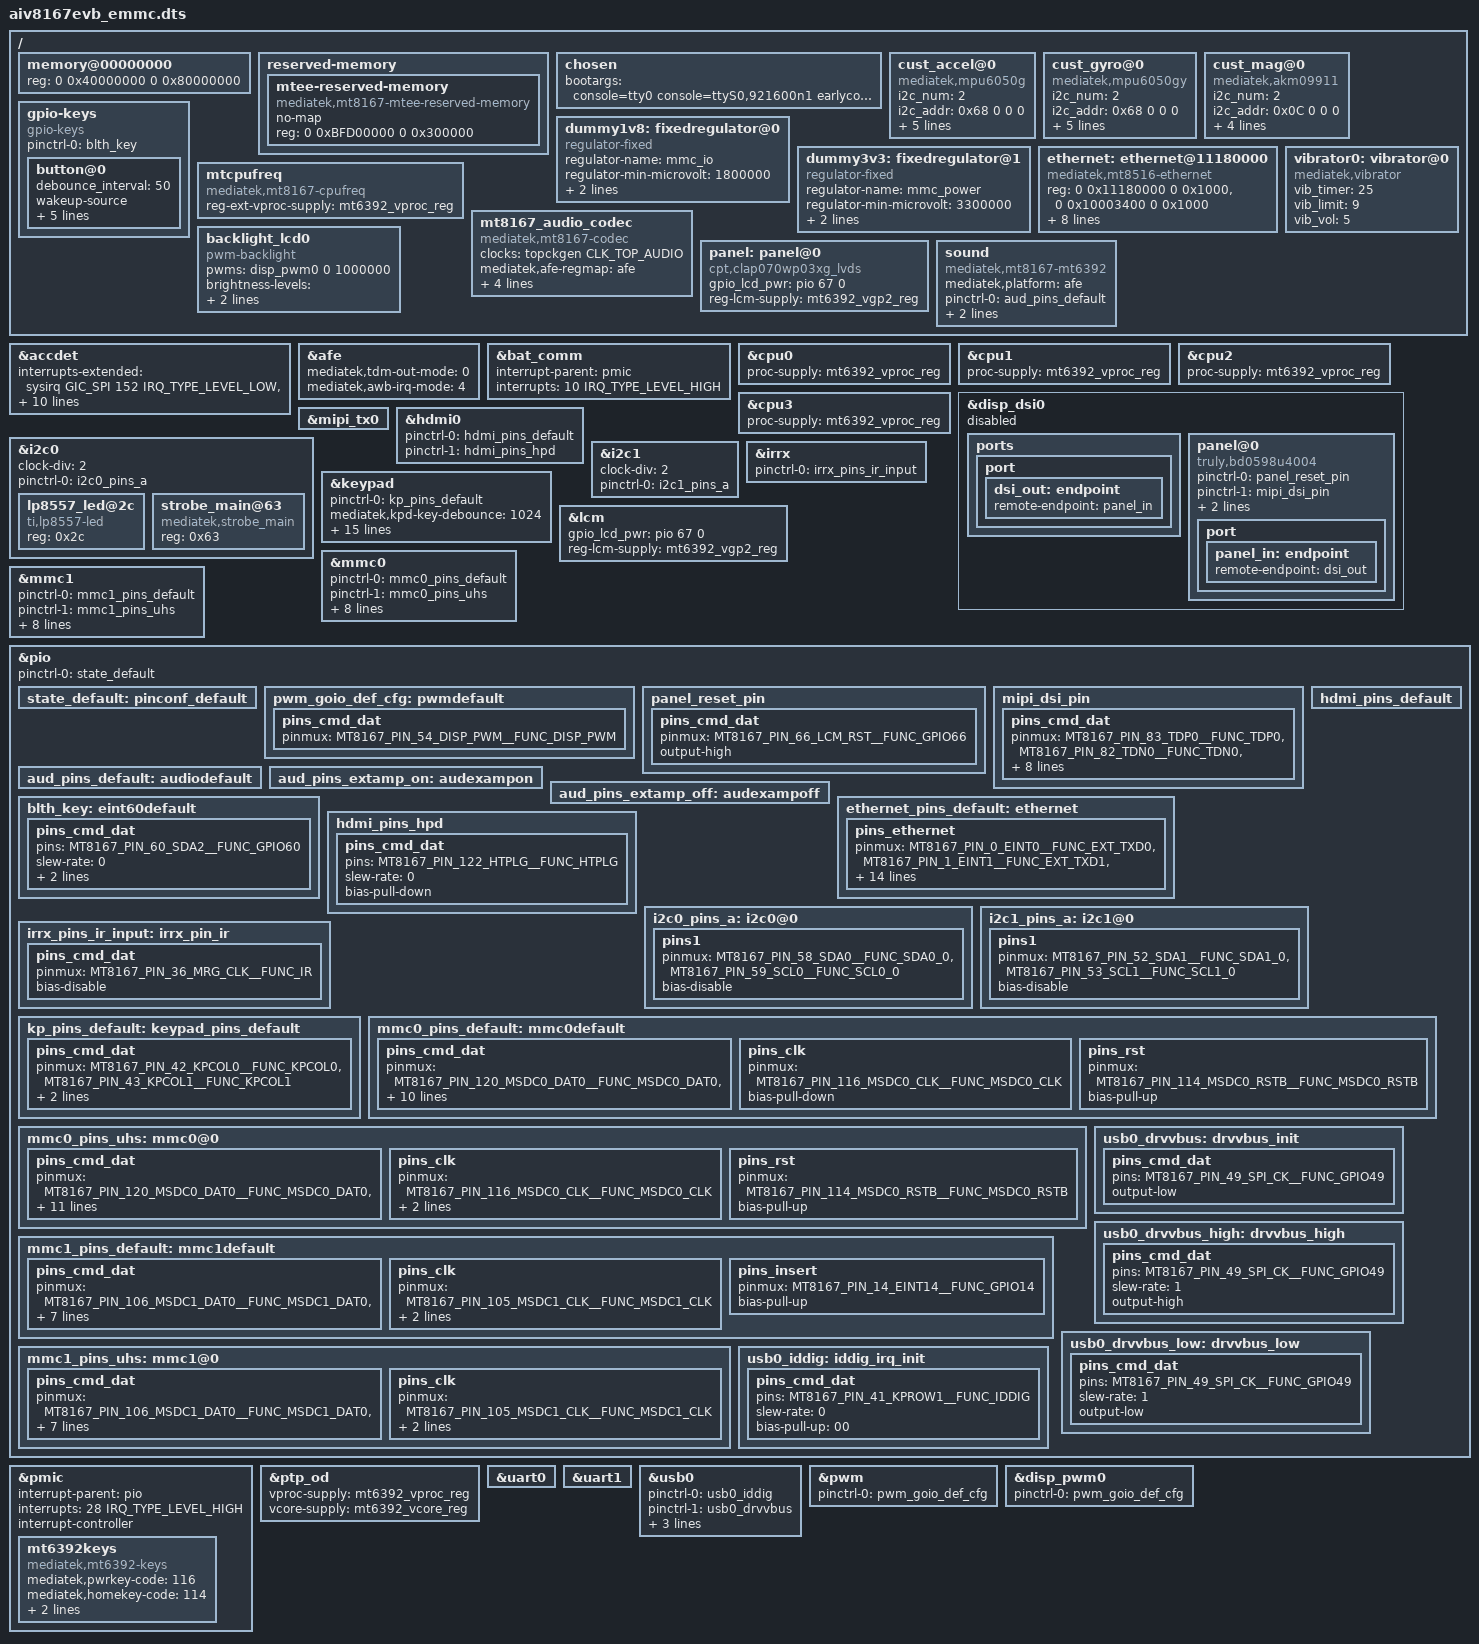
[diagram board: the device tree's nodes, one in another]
/*
 * Copyright (c) 2014-2015 MediaTek Inc.
 *
 * This program is free software; you can redistribute it and/or modify
 * it under the terms of the GNU General Public License version 2 as
 * published by the Free Software Foundation.
 *
 * This program is distributed in the hope that it will be useful,
 * MERCHANTABILITY or FITNESS FOR A PARTICULAR PURPOSE.  See the
 * GNU General Public License for more details.
 */

/dts-v1/;

#include "mt8167.dtsi"
#include "mt6392.dtsi"
#include <dt-bindings/gpio/gpio.h>

/ {
	/*
	IMPORTANT: 	If you modify the memory size,please modify mtee-reserved-memory size together.
					mtee must be located begin with the last 3MB of dram
	*/

	memory@00000000 {
		device_type = "memory";
		reg = <0 0x40000000 0 0x80000000>;
	};

	reserved-memory {
		mtee-reserved-memory {
			compatible = "mediatek,mt8167-mtee-reserved-memory";
			no-map;
			reg = <0 0xBFD00000 0 0x300000>;
		};
	};

	/* chosen */
	chosen {
		bootargs = "console=tty0 console=ttyS0,921600n1 earlycon=uart8250,mmio32,0x11005000 root=/dev/mmcblk0p7 vmalloc=496M androidboot.hardware=aud8516p1_linux";
	};

/* sensor standardization */
	cust_accel@0 {
		compatible = "mediatek,mpu6050g";
		i2c_num	= <2>;
		i2c_addr = <0x68 0 0 0>;
		direction = <7>;
		power_id = <0xffff>;
		power_vol = <0>;
		firlen = <0>;
		is_batch_supported = <0>;
	};

	cust_gyro@0 {
		compatible = "mediatek,mpu6050gy";
		i2c_num = <2>;
		i2c_addr = <0x68 0 0 0>;
		direction = <7>;
		power_id = <0xffff>;
		power_vol = <0>;
		firlen = <0>;
		is_batch_supported = <0>;
	};

	cust_mag@0 {
		compatible = "mediatek,akm09911";
		i2c_num = <2>;
		i2c_addr = <0x0C 0 0 0>;
		direction = <6>;
		power_id = <0xffff>;
		power_vol = <0>;
		is_batch_supported			= <0>;
	};
/* sensor gpio standization */

	dummy1v8: fixedregulator@0 {
		compatible = "regulator-fixed";
		regulator-name = "mmc_io";
		regulator-min-microvolt = <1800000>;
		regulator-max-microvolt = <1800000>;
		regulator-always-on;
	};

	dummy3v3: fixedregulator@1 {
		compatible = "regulator-fixed";
		regulator-name = "mmc_power";
		regulator-min-microvolt = <3300000>;
		regulator-max-microvolt = <3300000>;
		regulator-always-on;
	};

	ethernet: ethernet@11180000 {
		compatible = "mediatek,mt8516-ethernet";
		reg = <0 0x11180000 0 0x1000>,
		      <0 0x10003400 0 0x1000>;
		interrupts = <GIC_SPI 111 IRQ_TYPE_LEVEL_LOW>;
		eth-gpios = <&pio 34 0>;
		clocks = <&topckgen CLK_TOP_RG_ETH>,
			 <&topckgen CLK_TOP_66M_ETH>,
			 <&topckgen CLK_TOP_133M_ETH>;
		clock-names = "core", "reg", "trans";
		eth-regulator-supply = <&mt6392_vmch_reg>;
		pinctrl-names = "default";
		pinctrl-0 = <&ethernet_pins_default>;
		mac-address = [00 00 00 00 00 00];
		/*local-mac-address = [00 0C E7 06 00 00];*/
		status = "okay";
	};

	gpio-keys {
		compatible = "gpio-keys";
		pinctrl-names = "default";
		pinctrl-0 = <&blth_key>;

		button@0 {
			debounce_interval = <50>;
			wakeup-source;
			gpio-key,wakeup = <1>;
			gpios = <&pio 60 1>;
			label = "Bluetooth";
			linux,input-type = <0x1>;
			linux,code = <237>;
		};
	};

	mtcpufreq {
		compatible = "mediatek,mt8167-cpufreq";
		reg-ext-vproc-supply = <&mt6392_vproc_reg>;
	};

	mt8167_audio_codec: mt8167_audio_codec {
		compatible = "mediatek,mt8167-codec";
		clocks = <&topckgen CLK_TOP_AUDIO>;
		clock-names = "bus";
		mediatek,afe-regmap = <&afe>;
		mediatek,apmixedsys-regmap = <&apmixedsys>;
		mediatek,pwrap-regmap = <&pwrap>;
		mediatek,speaker-mode = <0>; /* 0(CLASSD) 1(CLASSAB) */
		mediatek,dmic-wire-mode = <1>; /* 0(ONE_WIRE) 1(TWO_WIRE) */
	};

	backlight_lcd0: backlight_lcd0 {
       compatible = "pwm-backlight";
       pwms = <&disp_pwm0 0 1000000>;
       brightness-levels = <
           0  16  32  48  64  80  96 112
           128 144 160 176 192 208 224 240
           255
       >;
       default-brightness-level = <5>;
	};

	panel: panel@0 {
		compatible = "cpt,clap070wp03xg_lvds";
		gpio_lcd_pwr = <&pio 67 0>;
		reg-lcm-supply = <&mt6392_vgp2_reg>;
	};



	sound: sound {
		compatible = "mediatek,mt8167-mt6392";
		mediatek,platform = <&afe>;
		pinctrl-names = "default", "extamp_on", "extamp_off";
		pinctrl-0 = <&aud_pins_default>;
		pinctrl-1 = <&aud_pins_extamp_on>;
		pinctrl-2 = <&aud_pins_extamp_off>;
		status = "okay";
	};

	vibrator0:vibrator@0 {
		compatible = "mediatek,vibrator";
		vib_timer = <25>;
		vib_limit = <9>;
		vib_vol= <5>;
	};
};

&accdet {
	interrupts-extended = <&sysirq GIC_SPI 152 IRQ_TYPE_LEVEL_LOW>,
			<&pio 16 IRQ_TYPE_LEVEL_HIGH>;
	eint-debounce = <256000>;
	accdet-gpio = <&pio 16 0>;
	accdet-mic-vol = <7>;
	headset-mode-setting = <0x500 0x500 1 0x1f0 0x800 0x800 0x20>;
	accdet-plugout-debounce = <20>;
	/*1:ACC mode, 2:low cost without in bias, 6:low cost with in bias*/
	accdet-mic-mode = <1>;
	/*0--MD_MAX--UP_MAX--DW_MAX*/
	headset-three-key-threshold = <0 80 220 500>;
	/*0--MD_MAX--VOICE_MAX--UP_MAX--DW_MAX*/
	headset-four-key-threshold = <0 58 121 192 450>;
	status = "okay";
};

&afe {
	/* 0(HDMI) 1(I2S) 2(TDM) */
	mediatek,tdm-out-mode = <0>;
	/* 0(IR1) 1(IRQ2) 4(IRQ7)*/
	mediatek,awb-irq-mode = <4>;
};

&bat_comm {
	interrupt-parent = <&pmic>;
	interrupts = <10 IRQ_TYPE_LEVEL_HIGH>;
};

&cpu0 {
	proc-supply = <&mt6392_vproc_reg>;
};

&cpu1 {
	proc-supply = <&mt6392_vproc_reg>;
};

&cpu2 {
	proc-supply = <&mt6392_vproc_reg>;
};

&cpu3 {
	proc-supply = <&mt6392_vproc_reg>;
};

&disp_dsi0 {
	status = "disabled";
	#address-cells = <1>;
	#size-cells = <0>;
	ports {
		port {
			dsi_out: endpoint {
				remote-endpoint = <&panel_in>;
			};
		};
	};

	panel@0 {
		compatible = "truly,bd0598u4004";
		pinctrl-names = "default", "mipi_dsi_pin";
		pinctrl-0 = <&panel_reset_pin>;
		pinctrl-1 = <&mipi_dsi_pin>;
		reset-gpios = <&pio 66 0>;
		reg = <0>;

		port {
			panel_in: endpoint {
				remote-endpoint = <&dsi_out>;
			};
		};
	};
};

&mipi_tx0 {
	status = "okay";
};

&hdmi0 {
	pinctrl-names = "default", "hdmi_hpd";
	pinctrl-0 = <&hdmi_pins_default>;
	pinctrl-1 = <&hdmi_pins_hpd>;
	status = "okay";
};

&i2c0 {
	clock-div = <2>;
	pinctrl-names = "default";
	pinctrl-0 = <&i2c0_pins_a>;
	status = "okay";

	lp8557_led@2c {
		compatible = "ti,lp8557-led";
		reg = <0x2c>;
	};

	strobe_main@63 {
		compatible = "mediatek,strobe_main";
		reg = <0x63>;
	};
};

&i2c1 {
	clock-div = <2>;
	pinctrl-names = "default";
	pinctrl-0 = <&i2c1_pins_a>;
	status = "okay";
};

&irrx {
	pinctrl-names = "default";
	pinctrl-0 = <&irrx_pins_ir_input>;
	status = "okay";
};

&keypad {
	pinctrl-names = "default";
	pinctrl-0 = <&kp_pins_default>;

	mediatek,kpd-key-debounce = <1024>;
	mediatek,kpd-sw-pwrkey = <116>;
	mediatek,kpd-hw-pwrkey = <8>;
	mediatek,kpd-sw-rstkey  = <114>;
	mediatek,kpd-hw-rstkey = <17>;
	mediatek,kpd-use-extend-type = <0>;
	/*HW Keycode [0~71] -> Linux Keycode*/
	mediatek,kpd-hw-map-num = <72>;
	mediatek,kpd-hw-init-map = <115 113 0 0 0 0 0 0 0 0 0 0 0 0 0 0 0 0 0 0 0 0 0 0
			0 0 0 0 0 0 0 0 0 0 0 0 0 0 0 0 0 0 0 0 0 0 0 0
			0 0 0 0 0 0 0 0 0 0 0 0 0 0 0 0 0 0 0 0 0 0 0 0 >;
	mediatek,kpd-pwrkey-eint-gpio = <0>;
	mediatek,kpd-pwkey-gpio-din  = <0>;
	mediatek,kpd-hw-dl-key0 = <0>;
	mediatek,kpd-hw-dl-key1 = <17>;
	mediatek,kpd-hw-dl-key2 = <8>;
	mediatek,kpd-hw-recovery-key = <17>;
	mediatek,kpd-hw-factory-key  = <0>;
};

&lcm {
	gpio_lcd_pwr = <&pio 67 0>;
	reg-lcm-supply = <&mt6392_vgp2_reg>;
};

&mmc0 {
	pinctrl-names = "default", "state_uhs";
	pinctrl-0 = <&mmc0_pins_default>;
	pinctrl-1 = <&mmc0_pins_uhs>;
	status = "okay";
	bus-width = <8>;
	max-frequency = <200000000>;
	cap-mmc-highspeed;
	mmc-hs200-1_8v;
	cap-mmc-hw-reset;
	vmmc-supply = <&mt6392_vemc3v3_reg>;
	vqmmc-supply = <&mt6392_vio18_reg>;
	non-removable;
};

&mmc1 {
	pinctrl-names = "default", "state_uhs";
	pinctrl-0 = <&mmc1_pins_default>;
	pinctrl-1 = <&mmc1_pins_uhs>;
	status = "okay";
	bus-width = <4>;
	max-frequency = <200000000>;
	cap-sd-highspeed;
	sd-uhs-sdr50;
	sd-uhs-sdr104;
	cd-gpios = <&pio 14 GPIO_ACTIVE_LOW>;
	vmmc-supply = <&mt6392_vmch_reg>;
	vqmmc-supply = <&mt6392_vmc_reg>;
};

&pio {
	pinctrl-names = "default";
	pinctrl-0 = <&state_default>;

	state_default:pinconf_default {
	};


pwm_goio_def_cfg: pwmdefault {
		pins_cmd_dat {
			pinmux = <MT8167_PIN_54_DISP_PWM__FUNC_DISP_PWM>;
			};
};
	panel_reset_pin: panel_reset_pin {
		pins_cmd_dat {
			pinmux = <MT8167_PIN_66_LCM_RST__FUNC_GPIO66>;
			output-high;
		};
	};

	mipi_dsi_pin: mipi_dsi_pin {
		pins_cmd_dat {
			pinmux = <MT8167_PIN_83_TDP0__FUNC_TDP0>,
				<MT8167_PIN_82_TDN0__FUNC_TDN0>,
				<MT8167_PIN_81_TDP1__FUNC_TDP1>,
				<MT8167_PIN_80_TDN1__FUNC_TDN1>,
				<MT8167_PIN_79_TCP__FUNC_TCP>,
				<MT8167_PIN_78_TCN__FUNC_TCN>,
				<MT8167_PIN_77_TDP2__FUNC_TDP2>,
				<MT8167_PIN_76_TDN2__FUNC_TDN2>,
				<MT8167_PIN_75_TDP3__FUNC_TDP3>,
				<MT8167_PIN_74_TDN3__FUNC_TDN3>;
		};
	};

	aud_pins_default: audiodefault {
	};
	aud_pins_extamp_on: audexampon {
	};

	aud_pins_extamp_off: audexampoff {
	};
	
	blth_key: eint60default {
		pins_cmd_dat {
			pins = <MT8167_PIN_60_SDA2__FUNC_GPIO60>;
			slew-rate = <0>;
			bias-pull-up = <MTK_PUPD_SET_R1R0_01>;
			input-enable;
		};
	};

	ethernet_pins_default: ethernet {
		pins_ethernet {
			pinmux = <MT8167_PIN_0_EINT0__FUNC_EXT_TXD0>,
				 <MT8167_PIN_1_EINT1__FUNC_EXT_TXD1>,
				 <MT8167_PIN_2_EINT2__FUNC_EXT_TXD2>,
				 <MT8167_PIN_3_EINT3__FUNC_EXT_TXD3>,
				 <MT8167_PIN_4_EINT4__FUNC_EXT_TXC>,
				 <MT8167_PIN_5_EINT5__FUNC_EXT_RXER>,
				 <MT8167_PIN_6_EINT6__FUNC_EXT_RXC>,
				 <MT8167_PIN_7_EINT7__FUNC_EXT_RXDV>,
				 <MT8167_PIN_8_EINT8__FUNC_EXT_RXD0>,
				 <MT8167_PIN_9_EINT9__FUNC_EXT_RXD1>,
				 <MT8167_PIN_10_EINT10__FUNC_EXT_RXD2>,
				 <MT8167_PIN_11_EINT11__FUNC_EXT_RXD3>,
				 <MT8167_PIN_12_EINT12__FUNC_EXT_TXEN>,
				 <MT8167_PIN_37_MRG_SYNC__FUNC_EXT_COL>,
				 <MT8167_PIN_38_MRG_DI__FUNC_EXT_MDIO>,
				 <MT8167_PIN_39_MRG_DO__FUNC_EXT_MDC>;
		};
	};

	hdmi_pins_default: hdmi_pins_default {
	};

	hdmi_pins_hpd: hdmi_pins_hpd {
		pins_cmd_dat {
			pins = <MT8167_PIN_122_HTPLG__FUNC_HTPLG>;
			slew-rate = <0>;
			bias-pull-down;
		};
	};

	i2c0_pins_a: i2c0@0 {
		pins1 {
			pinmux = <MT8167_PIN_58_SDA0__FUNC_SDA0_0>,
				 <MT8167_PIN_59_SCL0__FUNC_SCL0_0>;
			bias-disable;
		};
	};

	i2c1_pins_a: i2c1@0 {
		pins1 {
			pinmux = <MT8167_PIN_52_SDA1__FUNC_SDA1_0>,
				 <MT8167_PIN_53_SCL1__FUNC_SCL1_0>;
			bias-disable;
		};
	};

	irrx_pins_ir_input: irrx_pin_ir {
		pins_cmd_dat {
		pinmux = <MT8167_PIN_36_MRG_CLK__FUNC_IR>;
		bias-disable;
		};
	};

	kp_pins_default: keypad_pins_default {
		pins_cmd_dat {
			pinmux = <MT8167_PIN_42_KPCOL0__FUNC_KPCOL0>,
			     <MT8167_PIN_43_KPCOL1__FUNC_KPCOL1>;
			input-enable;
			bias-pull-up;
		};
	};

	mmc0_pins_default: mmc0default {
		pins_cmd_dat {
			pinmux = <MT8167_PIN_120_MSDC0_DAT0__FUNC_MSDC0_DAT0>,
				<MT8167_PIN_119_MSDC0_DAT1__FUNC_MSDC0_DAT1>,
				<MT8167_PIN_118_MSDC0_DAT2__FUNC_MSDC0_DAT2>,
				<MT8167_PIN_117_MSDC0_DAT3__FUNC_MSDC0_DAT3>,
				<MT8167_PIN_113_MSDC0_DAT4__FUNC_MSDC0_DAT4>,
				<MT8167_PIN_112_MSDC0_DAT5__FUNC_MSDC0_DAT5>,
				<MT8167_PIN_111_MSDC0_DAT6__FUNC_MSDC0_DAT6>,
				<MT8167_PIN_110_MSDC0_DAT7__FUNC_MSDC0_DAT7>,
				<MT8167_PIN_115_MSDC0_CMD__FUNC_MSDC0_CMD>;
			input-enable;
			bias-pull-up;
		};

		pins_clk {
			pinmux = <MT8167_PIN_116_MSDC0_CLK__FUNC_MSDC0_CLK>;
			bias-pull-down;
		};

		pins_rst {
			pinmux = <MT8167_PIN_114_MSDC0_RSTB__FUNC_MSDC0_RSTB>;
			bias-pull-up;
		};
	};

	mmc0_pins_uhs: mmc0@0{
		pins_cmd_dat {
			pinmux = <MT8167_PIN_120_MSDC0_DAT0__FUNC_MSDC0_DAT0>,
				<MT8167_PIN_119_MSDC0_DAT1__FUNC_MSDC0_DAT1>,
				<MT8167_PIN_118_MSDC0_DAT2__FUNC_MSDC0_DAT2>,
				<MT8167_PIN_117_MSDC0_DAT3__FUNC_MSDC0_DAT3>,
				<MT8167_PIN_113_MSDC0_DAT4__FUNC_MSDC0_DAT4>,
				<MT8167_PIN_112_MSDC0_DAT5__FUNC_MSDC0_DAT5>,
				<MT8167_PIN_111_MSDC0_DAT6__FUNC_MSDC0_DAT6>,
				<MT8167_PIN_110_MSDC0_DAT7__FUNC_MSDC0_DAT7>,
				<MT8167_PIN_115_MSDC0_CMD__FUNC_MSDC0_CMD>;
			input-enable;
			drive-strength = <MTK_DRIVE_6mA>;
			bias-pull-up = <MTK_PUPD_SET_R1R0_01>;
		};

		pins_clk {
			pinmux = <MT8167_PIN_116_MSDC0_CLK__FUNC_MSDC0_CLK>;
			drive-strength = <MTK_DRIVE_8mA>;
			bias-pull-down = <MTK_PUPD_SET_R1R0_10>;
		};

		pins_rst {
			pinmux = <MT8167_PIN_114_MSDC0_RSTB__FUNC_MSDC0_RSTB>;
			bias-pull-up;
		};
	};

	mmc1_pins_default: mmc1default {
		pins_cmd_dat {
			pinmux = <MT8167_PIN_106_MSDC1_DAT0__FUNC_MSDC1_DAT0>,
				<MT8167_PIN_107_MSDC1_DAT1__FUNC_MSDC1_DAT1>,
				<MT8167_PIN_108_MSDC1_DAT2__FUNC_MSDC1_DAT2>,
				<MT8167_PIN_109_MSDC1_DAT3__FUNC_MSDC1_DAT3>,
				<MT8167_PIN_104_MSDC1_CMD__FUNC_MSDC1_CMD>;
			input-enable;
			drive-strength = <MTK_DRIVE_6mA>;
			bias-pull-up = <MTK_PUPD_SET_R1R0_01>;
		};

		pins_clk {
			pinmux = <MT8167_PIN_105_MSDC1_CLK__FUNC_MSDC1_CLK>;
			drive-strength = <MTK_DRIVE_6mA>;
			bias-pull-down = <MTK_PUPD_SET_R1R0_10>;
		};

		pins_insert {
			pinmux = <MT8167_PIN_14_EINT14__FUNC_GPIO14>;
			bias-pull-up;
		};
	};

	mmc1_pins_uhs: mmc1@0 {
		pins_cmd_dat {
			pinmux = <MT8167_PIN_106_MSDC1_DAT0__FUNC_MSDC1_DAT0>,
				<MT8167_PIN_107_MSDC1_DAT1__FUNC_MSDC1_DAT1>,
				<MT8167_PIN_108_MSDC1_DAT2__FUNC_MSDC1_DAT2>,
				<MT8167_PIN_109_MSDC1_DAT3__FUNC_MSDC1_DAT3>,
				<MT8167_PIN_104_MSDC1_CMD__FUNC_MSDC1_CMD>;
			input-enable;
			drive-strength = <MTK_DRIVE_6mA>;
			bias-pull-up = <MTK_PUPD_SET_R1R0_01>;
		};

		pins_clk {
			pinmux = <MT8167_PIN_105_MSDC1_CLK__FUNC_MSDC1_CLK>;
			drive-strength = <MTK_DRIVE_8mA>;
			bias-pull-down = <MTK_PUPD_SET_R1R0_10>;
		};
	};

/* USB GPIO start */
	usb0_drvvbus: drvvbus_init {
		pins_cmd_dat {
			pins = <MT8167_PIN_49_SPI_CK__FUNC_GPIO49>;
			output-low;
		};
	};

	usb0_drvvbus_high: drvvbus_high {
		pins_cmd_dat {
			pins = <MT8167_PIN_49_SPI_CK__FUNC_GPIO49>;
			slew-rate = <1>;
			output-high;
		};
	};

	usb0_drvvbus_low: drvvbus_low {
		pins_cmd_dat {
			pins = <MT8167_PIN_49_SPI_CK__FUNC_GPIO49>;
			slew-rate = <1>;
			output-low;
		};
	};

	usb0_iddig: iddig_irq_init {
		pins_cmd_dat {
			pins = <MT8167_PIN_41_KPROW1__FUNC_IDDIG>;
			slew-rate = <0>;
			bias-pull-up = <00>;
		};
	};
/* USB GPIO end */
};

&pmic {
	interrupt-parent = <&pio>;
	interrupts = <28 IRQ_TYPE_LEVEL_HIGH>;
	interrupt-controller;
	#interrupt-cells = <2>;

	mt6392keys: mt6392keys {
		compatible = "mediatek,mt6392-keys";
		mediatek,pwrkey-code = <116>;
		mediatek,homekey-code = <114>;
		mediatek,long-press-mode = <0>;
		mediatek,long-press-duration = <0>;
	};
};

&ptp_od {
	vproc-supply = <&mt6392_vproc_reg>;
	vcore-supply = <&mt6392_vcore_reg>;
};

&uart0 {
	status="okay";
};

&uart1 {
	status="okay";
};

&usb0 {
	pinctrl-names = "iddig_irq_init", "drvvbus_init", "drvvbus_low", "drvvbus_high";
	pinctrl-0 = <&usb0_iddig>;
	pinctrl-1 = <&usb0_drvvbus>;
	pinctrl-2 = <&usb0_drvvbus_low>;
	pinctrl-3 = <&usb0_drvvbus_high>;
	status = "okay";
	drvvbus_gpio = <&pio 49 2>;
};

&pwm {
	pinctrl-names = "default";
	pinctrl-0 = <&pwm_goio_def_cfg>;
	status = "okay";
};

&disp_pwm0 {
	pinctrl-names = "default";
	pinctrl-0 = <&pwm_goio_def_cfg>;
	status = "okay";
};
